# D2522AA register map
Vendor: Dialog; Series: D2522AA; File version: 1.2
CPU: CM0 r1p0, little endian, MPU, FPU, 3 interrupt priority bits
Registers are 32-bit, read-write, reset 0x0 unless marked. A register's access mark holds for its fields unless they carry their own. Offsets are from the block's base; [hi:lo] are bit positions; 'fields as' and 'values as' point back to an identical list.

## CRG_PER — CRG_PER registers
Base 0x50030C00
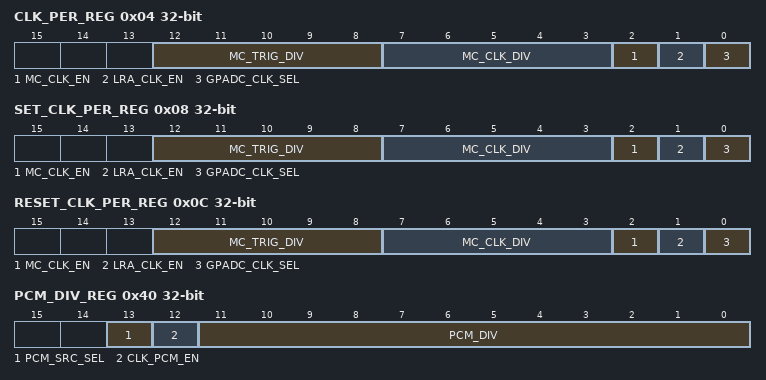
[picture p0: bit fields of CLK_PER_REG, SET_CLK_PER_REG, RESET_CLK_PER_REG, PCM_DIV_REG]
0x04 CLK_PER_REG — Peripheral divider register
  [12:8] MC_TRIG_DIV — Trigger divider for the motor controller 0x0: divide LP_CLK by 1 0x1: divide LP_CLK by 2 ... 0x1F: divide LP_CLK by 32
  [7:3] MC_CLK_DIV — Clock divider for the motor controller slot. The slots are clocked on (a PCLK synchronized version of) the LP clock, and can be further divided by this divider: 0x0: divide LP clock by 1 0x1: divide LP clock by 2 ... 0x1F: divide LP clock by 32
  [2] MC_CLK_EN — Enables the clock
  [1] LRA_CLK_EN — Enables the clock
  [0] GPADC_CLK_SEL — Selects the clock source 1 = DIV1 clock 0 = DIVN clock/ 2
0x08 SET_CLK_PER_REG — Peripheral divider register SET register, reads 0x0000
  [12:8] MC_TRIG_DIV rw-once — Trigger divider for the motor controller 0x0: divide LP_CLK by 1 0x1: divide LP_CLK by 2 ... 0x1F: divide LP_CLK by 32
  [7:3] MC_CLK_DIV rw-once — Clock divider for the motor controller slot. The slots are clocked on (a PCLK synchronized version of) the LP clock, and can be further divided by this divider: 0x0: divide LP clock by 1 0x1: divide LP clock by 2 ... 0x1F: divide LP clock by 32
  [2] MC_CLK_EN rw-once — Enables the clock
  [1] LRA_CLK_EN rw-once — Enables the clock
  [0] GPADC_CLK_SEL rw-once — Selects the clock source 1 = DIV1 clock 0 = DIVN clock/ 2
0x0C RESET_CLK_PER_REG — Peripheral divider register RESET register, reads 0x0000
  fields as CLK_PER_REG
0x40 PCM_DIV_REG — PCM divider and enables
  [13] PCM_SRC_SEL — Selects the clock source 1 = DIV1 clock 0 = DIVN clock
  [12] CLK_PCM_EN — Enable for the internally generated PCM clock The PCM_DIV must be set before or together with CLK_PCM_EN.
  [11:0] PCM_DIV — PCM clock divider
0x44 PCM_FDIV_REG — PCM fractional division register
  [15:0] PCM_FDIV — These bits define the fractional division part of the PCM clock. The left most '1' defines the denominator, the number of '1' bits define the numerator. E.g. 0x0110 means 2/9, with a distribution of 1.0001.0000 0xfeee means 13/16, with a distribution of 1111.1110.1110.1110
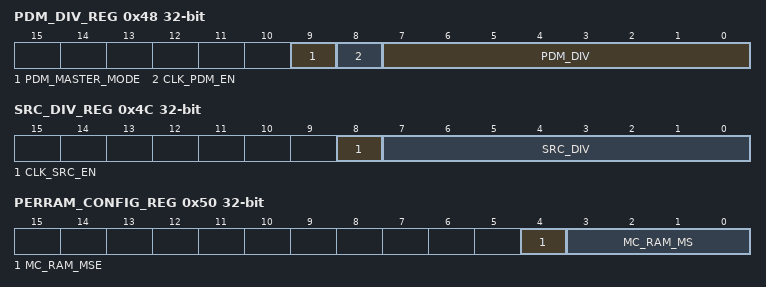
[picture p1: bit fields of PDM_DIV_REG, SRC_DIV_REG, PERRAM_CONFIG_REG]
0x48 PDM_DIV_REG — PDM divider and enables
  [9] PDM_MASTER_MODE — Master mode selection 0: slave mode 1: master mode
  [8] CLK_PDM_EN — Enable for the internally generated PDM clock The PDM_DIV must be set before or together with CLK_PDM_EN.
  [7:0] PDM_DIV — PDM clock divider
0x4C SRC_DIV_REG — SRC divider and enables
  [8] CLK_SRC_EN — Enable for the internally generated SRC clock The SRC_DIV must be set before or together with CLK_SRC_EN.
  [7:0] SRC_DIV — SRC clock divider
0x50 PERRAM_CONFIG_REG — Peripheral RAM configurations
  [4] MC_RAM_MSE — Margin overrule enable
  [3:0] MC_RAM_MS — Margin setting for RAM

## CRG_SYS — CRG_SYS registers
Base 0x50040500
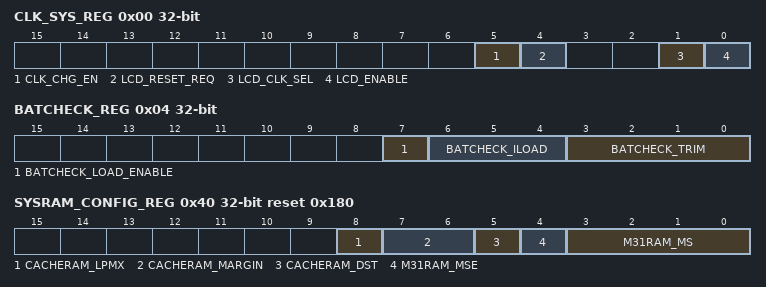
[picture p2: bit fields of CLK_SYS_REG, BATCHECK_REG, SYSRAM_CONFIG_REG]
0x00 CLK_SYS_REG — Peripheral divider register
  [5] CLK_CHG_EN — Enables the clocks for the charger FSM block
  [4] LCD_RESET_REQ — Generates a SW reset towards the LCD controller.
  [1] LCD_CLK_SEL — Selects the clock source 1 = DIV1 clock 0 = DIVN clock
  [0] LCD_ENABLE — Enables the clock
0x04 BATCHECK_REG
  [7] BATCHECK_LOAD_ENABLE — Enable a current load on the battery.
  [6:4] BATCHECK_ILOAD — Set the current load to (ILOAD+1) mA.
  [3:0] BATCHECK_TRIM — Trim the current load with steps of 2.7% from -19.1% to +19.1%. 0: +0.0% , 8: -0% 1: +2.7% , 9: -2.7% 2: +5.5% , 10: -5.5% 3: +8.2% , 11: -8.2% 4: +10.9% , 12: -10.9% 5: +13.6% , 13: -13.6% 6: +16.4% , 14: -16.4% 7: +19.1% , 15: -19.1%
0x40 SYSRAM_CONFIG_REG reset 0x180 — System RAM configurations
  [8] CACHERAM_LPMX — LPM Enable. Asynchronous. Active low. Asserting lpmx low will enable the leakage reduction circuit to the memory cells.
  [7:6] CACHERAM_MARGIN — Margin Control. Asynchronous. Recommended setting is 2b10. These bits control the read and write margin. 2b00 provides the highest margin (slowest). 2b11 provides the least margin (fastest).
  [5] CACHERAM_DST — Disable Self Time. Asynchronous. Active high. When asserted high, dst overrides the self-timed circuitry and causes the read and write margin to be fixed by the falling edge of clk. This mode is only enabled if margin is set to 2b00 (slowest setting). dst should be set low during normal operation.
  [4] M31RAM_MSE — Margin overrule enable for CRYPTO, QSPIC and USB RAM
  [3:0] M31RAM_MS — Margin setting for CRYPTO, QSPIC and USB RAM
